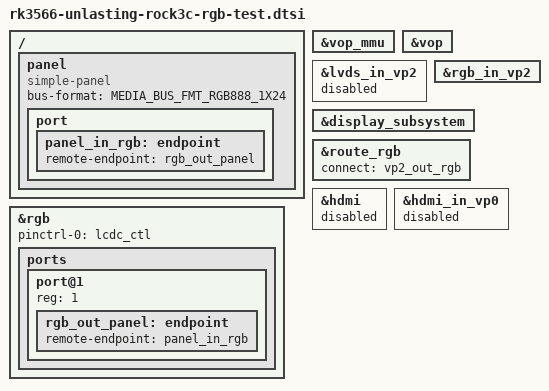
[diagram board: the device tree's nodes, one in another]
// SPDX-License-Identifier: (GPL-2.0+ OR MIT)
/*
 * Copyright (c) 2024 Rockchip Electronics Co., Ltd.
 *
 */
#include <dt-bindings/display/media-bus-format.h>

/ {
	panel: panel {
		compatible = "simple-panel";
		bus-format = <MEDIA_BUS_FMT_RGB888_1X24>;
		status = "okay";
/*
		display-timings {
			native-mode = <&q7050ith2641aa1t_timing>;

			q7050ith2641aa1t_timing: timing0 {
				clock-frequency = <51200000>;
				hactive = <1024>;
				vactive = <600>;
				hback-porch = <160>;
				hfront-porch = <160>;
				vback-porch = <23>;
				vfront-porch = <12>;
				hsync-len = <24>;
				vsync-len = <2>;
				hsync-active = <0>;
				vsync-active = <0>;
				de-active = <0>;
				pixelclk-active = <0>;
			};
		};
*/
		port {
			panel_in_rgb: endpoint {
				remote-endpoint = <&rgb_out_panel>;
			};
		};
	};
};


//======================================//
&rgb {
	status = "okay";
	pinctrl-names = "default";
	pinctrl-0 = <&lcdc_ctl>;

	ports {
		port@1 {
			reg = <1>;

			rgb_out_panel: endpoint {
				remote-endpoint = <&panel_in_rgb>;
			};
		};
	};
};

&vop_mmu {
	status = "okay";
};

&vop {
	status = "okay";
};

&lvds_in_vp2 {
	status = "disabled";
};

&rgb_in_vp2 {
	status = "okay";
};

&display_subsystem {
	status = "okay";
};

&route_rgb {
	status = "okay";
	connect = <&vp2_out_rgb>;
};

/* ==================================== */
&hdmi {
	status = "disabled";
};

&hdmi_in_vp0 {
	status = "disabled";
};
